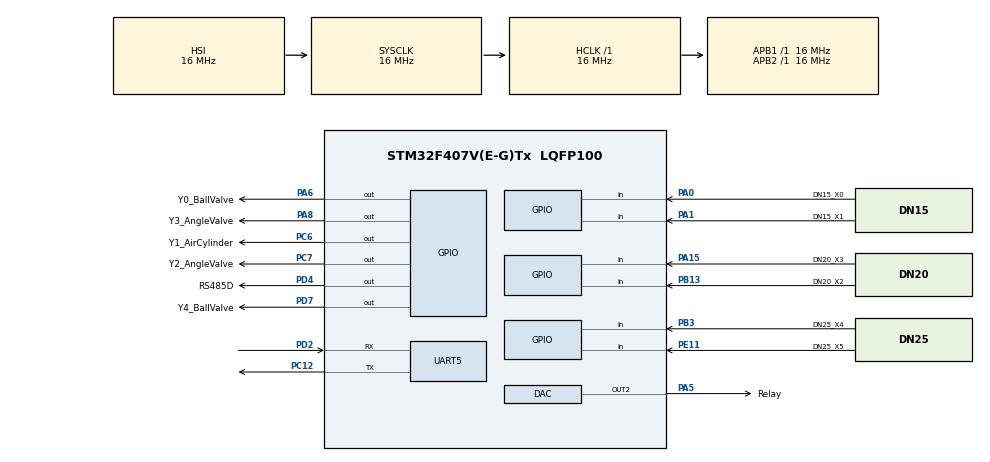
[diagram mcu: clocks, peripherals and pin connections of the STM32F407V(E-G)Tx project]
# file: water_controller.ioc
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Mcu.Family=STM32F4
Mcu.Name=STM32F407V(E-G)Tx
Mcu.Package=LQFP100
NVIC.PriorityGroup=NVIC_PRIORITYGROUP_4
PA0-WKUP.GPIO_Label=DN15_X0
PA0-WKUP.GPIO_PuPd=GPIO_NOPULL
PA0-WKUP.Signal=GPIO_Input
PA1.GPIO_Label=DN15_X1
PA1.GPIO_PuPd=GPIO_NOPULL
PA1.Signal=GPIO_Input
PA13.Mode=Serial_Wire
PA13.Signal=SYS_JTMS-SWDIO
PA14.Mode=Serial_Wire
PA14.Signal=SYS_JTCK-SWCLK
PA15.GPIO_Label=DN20_X3
PA15.GPIO_PuPd=GPIO_NOPULL
PA15.Signal=GPIO_Input
PA5.GPIO_Label=Relay
PA5.Signal=COMP_DAC2_group
PA6.GPIO_Label=Y0_BallValve
PA6.Signal=GPIO_Output
PA8.GPIO_Label=Y3_AngleValve
PA8.Signal=GPIO_Output
PB13.GPIO_Label=DN20_X2
PB13.GPIO_PuPd=GPIO_NOPULL
PB13.Signal=GPIO_Input
PB3.GPIO_Label=DN25_X4
PB3.GPIO_PuPd=GPIO_NOPULL
PB3.Signal=GPIO_Input
PC12.GPIO_PuPd=GPIO_PULLUP
PC12.Mode=Asynchronous
PC12.Signal=UART5_TX
PC6.GPIO_Label=Y1_AirCylinder
PC6.Signal=GPIO_Output
PC7.GPIO_Label=Y2_AngleValve
PC7.Signal=GPIO_Output
PD2.GPIO_PuPd=GPIO_PULLUP
PD2.Mode=Asynchronous
PD2.Signal=UART5_RX
PD4.GPIO_Label=RS485D
PD4.Signal=GPIO_Output
PD7.GPIO_Label=Y4_BallValve
PD7.Signal=GPIO_Output
PE11.GPIO_Label=DN25_X5
PE11.GPIO_PuPd=GPIO_NOPULL
PE11.Signal=GPIO_Input
ProjectManager.HeapSize=0x200
ProjectManager.StackSize=0x400
ProjectManager.TargetToolchain=CMake
RCC.AHBFreq_Value=16000000
RCC.APB1Freq_Value=16000000
RCC.APB2Freq_Value=16000000
RCC.CortexFreq_Value=16000000
RCC.HSE_VALUE=25000000
RCC.HSI_VALUE=16000000
RCC.LSE_VALUE=32768
RCC.SYSCLKFreq_VALUE=16000000
RCC.VCOOutputFreq_Value=192000000
SH.COMP_DAC2_group.0=DAC_OUT2,DAC_OUT2
UART5.VirtualMode=Asynchronous
board=custom

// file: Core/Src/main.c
/* USER CODE BEGIN Header */
/**
  ******************************************************************************
  * @file           : main.c
  * @brief          : Main program body
  ******************************************************************************
  * @attention
  *
  * Copyright (c) 2026 STMicroelectronics.
  * All rights reserved.
  *
  * This software is licensed under terms that can be found in the LICENSE file
  * in the root directory of this software component.
  * If no LICENSE file comes with this software, it is provided AS-IS.
  *
  ******************************************************************************
  */
/* USER CODE END Header */
#include "main.h"
#include "dac.h"
#include "usart.h"
#include "gpio.h"

/* USER CODE BEGIN Includes */
#include "modbus.h"
#include "valve.h"

/* USER CODE END Includes */

void SystemClock_Config(void);

int main(void)
{

  /* MCU Configuration--------------------------------------------------------*/

  /* Reset of all peripherals, Initializes the Flash interface and the Systick. */
  HAL_Init();

  /* Configure the system clock */
  SystemClock_Config();

  /* Initialize all configured peripherals */
  MX_GPIO_Init();
  MX_DAC_Init();
  MX_UART5_Init();
  /* USER CODE BEGIN 2 */
	if (HAL_DAC_SetValue(&hdac, DAC_CHANNEL_2, DAC_ALIGN_12B_R, 4095/2) != HAL_OK)
	{
		Error_Handler();
	}
	 if (HAL_DAC_Start(&hdac, DAC_CHANNEL_2) != HAL_OK)
	 {
		 Error_Handler();
	 }
  frock_state frock;
  /* USER CODE END 2 */

  /* Infinite loop */
  /* USER CODE BEGIN WHILE */
  /* 初值设为高：如果上电时X3已经为低，第一次读取也会触发打开。 */
  GPIO_PinState last_x2 = GPIO_PIN_SET;
  uint8_t valve_state = 0;
  while (1)
  {
    GPIO_PinState current_x2 = DN20_X2();
    Modbus_ReadFlow(1, &flow_value);
    if (last_x2 == GPIO_PIN_SET && current_x2 == GPIO_PIN_RESET)
    {
      if (valve_state == 0)
      {
        valve_state = 1;
        open_valve();
      }
      else
      {
        valve_state = 0;
        if (flow_value <= 1)
        {
          angle_valve_blow();
          close_valve();
        }

      }
    }
    last_x2 = current_x2;

  }
  /* USER CODE END 3 */
}

void SystemClock_Config(void)
{
  RCC_OscInitTypeDef RCC_OscInitStruct = {0};
  RCC_ClkInitTypeDef RCC_ClkInitStruct = {0};

  /** Configure the main internal regulator output voltage
  */
  __HAL_RCC_PWR_CLK_ENABLE();
  __HAL_PWR_VOLTAGESCALING_CONFIG(PWR_REGULATOR_VOLTAGE_SCALE1);

  /** Initializes the RCC Oscillators according to the specified parameters
  * in the RCC_OscInitTypeDef structure.
  */
  RCC_OscInitStruct.OscillatorType = RCC_OSCILLATORTYPE_HSI;
  RCC_OscInitStruct.HSIState = RCC_HSI_ON;
  RCC_OscInitStruct.HSICalibrationValue = RCC_HSICALIBRATION_DEFAULT;
  RCC_OscInitStruct.PLL.PLLState = RCC_PLL_NONE;
  if (HAL_RCC_OscConfig(&RCC_OscInitStruct) != HAL_OK)
  {
    Error_Handler();
  }

  /** Initializes the CPU, AHB and APB buses clocks
  */
  RCC_ClkInitStruct.ClockType = RCC_CLOCKTYPE_HCLK|RCC_CLOCKTYPE_SYSCLK
                              |RCC_CLOCKTYPE_PCLK1|RCC_CLOCKTYPE_PCLK2;
  RCC_ClkInitStruct.SYSCLKSource = RCC_SYSCLKSOURCE_HSI;
  RCC_ClkInitStruct.AHBCLKDivider = RCC_SYSCLK_DIV1;
  RCC_ClkInitStruct.APB1CLKDivider = RCC_HCLK_DIV1;
  RCC_ClkInitStruct.APB2CLKDivider = RCC_HCLK_DIV1;

  if (HAL_RCC_ClockConfig(&RCC_ClkInitStruct, FLASH_LATENCY_0) != HAL_OK)
  {
    Error_Handler();
  }
}

void Error_Handler(void)
{
  __disable_irq();
  while (1)
  {
  }
}
